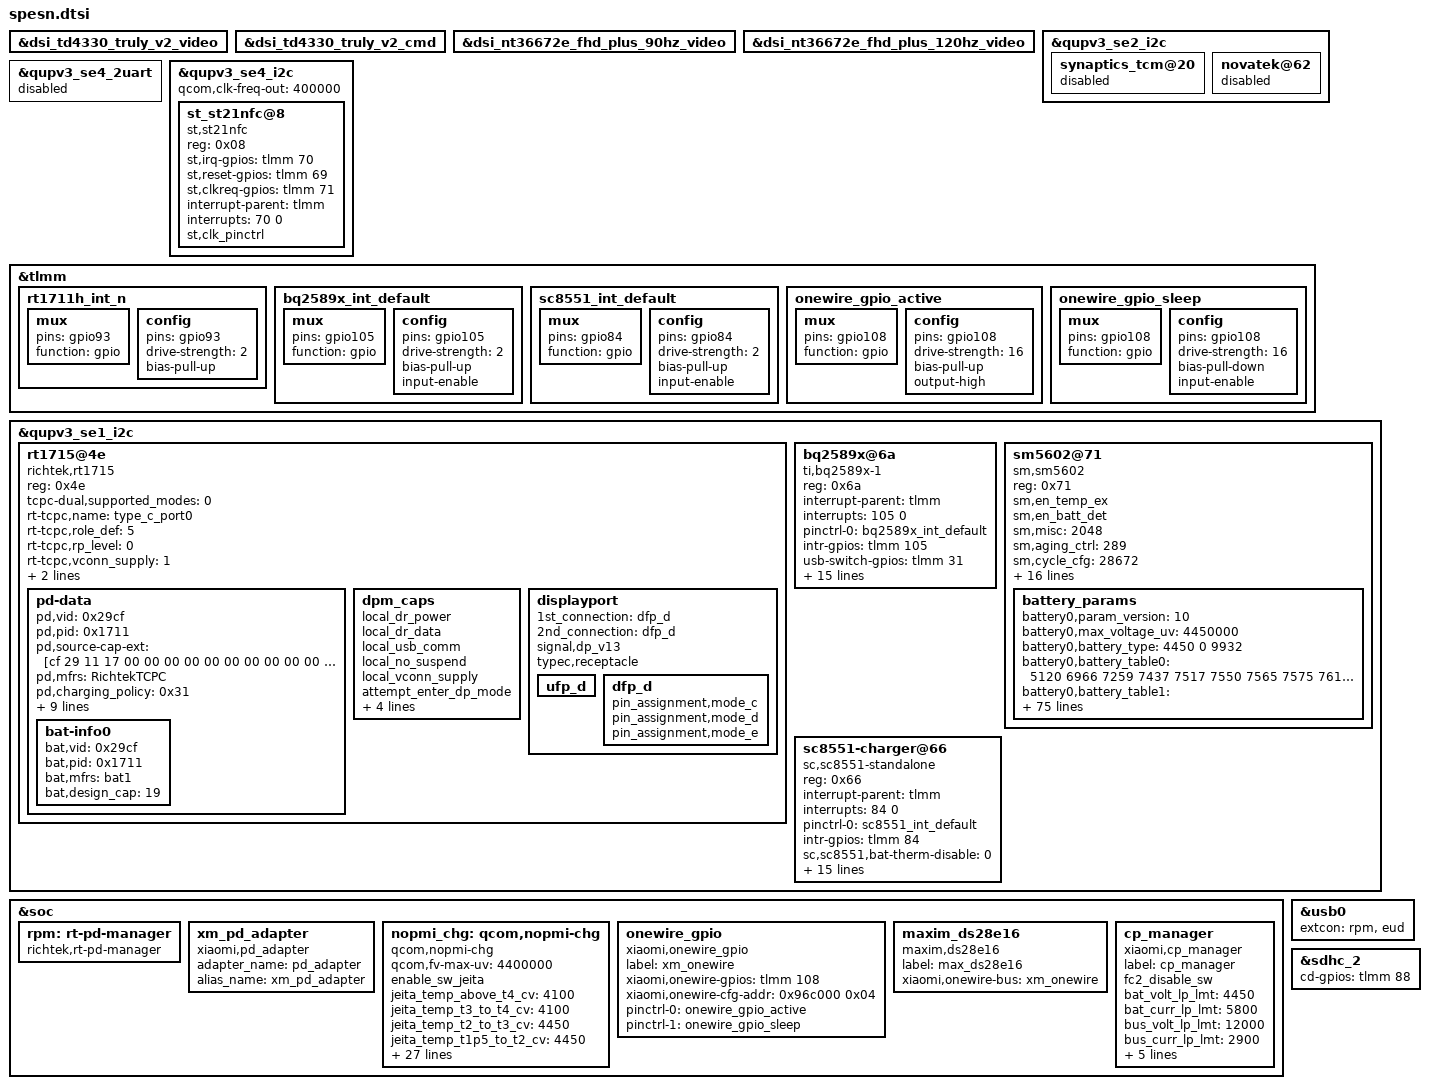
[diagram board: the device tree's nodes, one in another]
#include "khaje-idp.dtsi"

&dsi_td4330_truly_v2_video {
	/delete-property/ qcom,esd-check-enabled;
};

&dsi_td4330_truly_v2_cmd {
	/delete-property/ qcom,esd-check-enabled;
};

&dsi_nt36672e_fhd_plus_90hz_video {
	/delete-property/ qcom,esd-check-enabled;
};

&dsi_nt36672e_fhd_plus_120hz_video {
	/delete-property/ qcom,esd-check-enabled;
};

&qupv3_se2_i2c {
	synaptics_tcm@20 {
		status = "disabled";
	};

	novatek@62 {
		status = "disabled";
	};
};

&qupv3_se4_2uart {
	status = "disabled";
};

/* Spes NFC */
&qupv3_se4_i2c {
	status = "ok";
	qcom,clk-freq-out = <400000>;
	#address-cells = <1>;
	#size-cells = <0>;

	st_st21nfc@8 {
		compatible = "st,st21nfc";
		reg = <0x08>;
		st,irq-gpios = <&tlmm 70 0>;
		st,reset-gpios = <&tlmm 69 0>;
		st,clkreq-gpios = <&tlmm 71 0>;
		interrupt-parent = <&tlmm>;
		interrupts = <70 0>;
		interrupt-names = "nfc_irq";
		clock-names = "nfc_ref_clk";
		st,clk_pinctrl;
	};
};

&tlmm {
	/* RT1711H - TCPC */
	rt1711h_int_n: rt1711h_int_n {
		mux {
			pins = "gpio93";
			function = "gpio";
		};

		config {
			pins = "gpio93";
			drive-strength = <2>;
			bias-pull-up;
		};
	};

	/* BQ-CHARGER */
	bq2589x_int_default: bq2589x_int_default {
		mux {
			pins = "gpio105";
			function = "gpio";
		};

		config {
			pins = "gpio105";
			drive-strength = <2>;
			bias-pull-up;
			input-enable;
		};
	};

	/* sc8551-charger */
	sc8551_int_default: sc8551_int_default {
		mux {
			pins = "gpio84";
			function = "gpio";
		};

		config {
			pins = "gpio84";
			drive-strength = <2>;
			bias-pull-up;
			input-enable;
		};
	};

	/* Onewire */
	onewire_gpio_active: onewire_gpio_active {
		mux {
			pins = "gpio108";
			function = "gpio";
		};

		config {
			pins = "gpio108";
			drive-strength = <16>;
			bias-pull-up;
			output-high;
		};
	};

	onewire_gpio_sleep: onewire_gpio_sleep {
		mux {
			pins = "gpio108";
			function = "gpio";
		};

		config {
			pins = "gpio108";
			drive-strength = <16>;
			bias-pull-down;
			input-enable;
		};
	};
};

&qupv3_se1_i2c {
	status = "ok";
	#address-cells = <1>;
	#size-cells = <0>;

	/* TCPC: Richtek RT1715 Type-C PD Controller */
	rt1715@4e {
		compatible = "richtek,rt1715";
		reg = <0x4e>;
		status = "okay";
		tcpc-dual,supported_modes = <0>;
		rt-tcpc,name = "type_c_port0";
		/* 0: Unknown, 1: SNK, 2: SRC, 3: DRP, 4: Try.SRC, 5: Try.SNK */
		rt-tcpc,role_def = <5>;
		/* 0: Default, 1: 1.5A, 2: 3.0A */
		rt-tcpc,rp_level = <0>;
		/* 0: Never, 1: Always, 2: EMarkOnly, 3: StartOnly */
		rt-tcpc,vconn_supply = <1>;
		rt1711hpd,intr-gpios = <&tlmm 93 0>;
		pinctrl-names = "default";
		pinctrl-0 = <&rt1711h_int_n>;

		pd-data {
			pd,vid = <0x29cf>;
			pd,pid = <0x1711>;
			pd,source-cap-ext = [cf 29 11 17 00 00 00 00 00 00 00 00 00 00 00 00 00 00 00 00 00 00 00 02 00];
			pd,mfrs = "RichtekTCPC";
			/*
			 * VSAFE5V = 0x00, MAX_POWER = 0x01, CUSTOM = 0x02
			 * MAX_POWER_LV = 0x21, MAX_POWER_LVIC = 0x31
			 * MAX_POWER_HV = 0x41, MAX_POWER_HVIC = 0x51
			 */
			pd,charging_policy = <0x31>;

			/*
			 * Fixed 5V, 500 mA = <0x00019032>
			 * Fixed 5V, 1A = <0x00019064>
			 * Fixed 5V, 1.5A = <0x00019096>
			 * Fixed 5V, 2A = <0x000190c8>
			 * Fixed 5V, 3A = <0x0001912c>
			 * Fixed 9V, 500 mA = <0x0002d032>
			 * Fixed 9V, 1A = <0x0002d064>
			 * Fixed 9V, 2A = <0x0002d0c8>
			 * Fixed 9V, 3A = <0x0002d12c>
			 * Variable 5-9V, 1A = <0x8642d064>
			 * Variable 5-9V, 2A = <0x8642d0c8>
			 * Variable 5-9V, 3A = <0x8642d12c>
			 * PPS 3V ~ 5.9V, 3A = <0xC0761E3C>
			 * PPS 5V ~ 11.0V, 3A = <0xC0DC323C>
			 */
			pd,source-pdo-size = <1>;
			pd,source-pdo-data = <0x00019032>;
			pd,sink-pdo-size = <1>;
			pd,sink-pdo-data = <0x000190c8>;
			pd,id-vdo-size = <6>;
			pd,id-vdo-data = <0xd14029cf 0x0 0x17110000 0x61000000 0x0 0x41000000>;
			bat,nr = <1>;
			pd,country_nr = <0>;
			bat-info0 {
				bat,vid = <0x29cf>;
				bat,pid = <0x1711>;
				bat,mfrs = "bat1";
				bat,design_cap = <19>;
			};
		};

		dpm_caps {
			local_dr_power;
			local_dr_data;
			local_usb_comm;
			local_no_suspend;
			local_vconn_supply;
			attempt_enter_dp_mode;
			attempt_discover_cable;
			attempt_discover_id;
			pr_check = <0>;
			dr_check = <0>;
		};

		displayport {
			1st_connection = "dfp_d";
			2nd_connection = "dfp_d";
			signal,dp_v13;
			typec,receptacle;

			ufp_d {};

			dfp_d {
				pin_assignment,mode_c;
				pin_assignment,mode_d;
				pin_assignment,mode_e;
			};
		};
	};

	/* BQ charger */
	bq2589x@6a {
		compatible = "ti,bq2589x-1";
		reg = <0x6a>;
		interrupt-parent = <&tlmm>;
		interrupts = <105 0>;
		pinctrl-names = "default";
		pinctrl-0 = <&bq2589x_int_default>;
		intr-gpios = <&tlmm 105 0>;
		usb-switch-gpios = <&tlmm 31 0>;
		ti,bq2589x,vbus-volt-high-level = <8700>;
		ti,bq2589x,vbus-volt-low-level = <4400>;
		ti,bq2589x,vbat-min-volt-to-tuneup = <3000>;
		ti,bq2589x,charge-voltage = <4450>;
		ti,bq2589x,charge-current = <2000>;
		ti,bq2589x,charge-current-1500 = <1500>;
		ti,bq2589x,charge-current-1000 = <1000>;
		ti,bq2589x,charge-current-500 = <500>;
		ti,bq2589x,charge-current-3500 = <3500>;
		ti,bq2589x,input-current-2000 = <2000>;
		ti,bq2589x,term-current = <256>;
		ti,bq2589x,enable-auto-dpdm;
		ti,bq2589x,enable-termination;
		ti,bq2589x,enable-ico;
		ti,bq2589x,use-absolute-vindpm;
	};

	/* Fuel gauge */
	sm5602@71 {
		compatible = "sm,sm5602";
		reg = <0x71>;
		sm,en_temp_ex;
		sm,en_batt_det;
		sm,misc = <2048>;
		sm,aging_ctrl = <289>;
		sm,cycle_cfg = <28672>;
		sm,rsns = <0>;
		sm,fg_irq_set = <2047>;
		sm,low_soc1 = <1>;
		sm,low_soc2 = <15>;
		sm,v_l_alarm = <3400>;
		sm,v_h_alarm = <4450>;
		sm,battery_table_num = <0>;
		sm,param_version = <5>;
		sm,t_l_alarm_in = <54>;
		sm,t_h_alarm_in = <1>;
		sm,t_l_alarm_ex = <54834>;
		sm,t_h_alarm_ex = <38239>;
		sm,shutdown-delay-enable;
		sm,rtrace = <7300>;
		sm,soc_decimal_rate = <0 38 10 35 20 33 30 33 40 33 50 33 60 33 70 30 80 25 90 20 95 10>;

		battery_params {
			/* battery 0 */
			battery0,param_version = <10>;
			battery0,max_voltage_uv = <4450000>;
			battery0,battery_type = <4450 0 9932>;
			battery0,battery_table0 = <5120 6966 7259 7437 7517 7550 7565 7575 7617 7664 7706 7754 7786 7842 7918 7991 8121 8213 8313 8424 8604 8791 9041 9420>;
			battery0,battery_table1 = <0 102 490 879 1138 1396 2044 2820 3597 4632 5927 7221 8515 10457 12398 13692 14987 16281 17575 18869 20811 22752 25600 25830>;
			battery0,battery_table2 = <5664 4371 3856 3342 3084 2827 2570 2570>;
			battery0,alpha = <204>;
			battery0,beta = <37>;
			battery0,rs = <95>;
			battery0,rs_value = <80 266 14336 72>;
			battery0,vit_period = <12890>;
			battery0,volt_cal = <32768>;
			battery0,mix_value = <3>;
			battery0,curr_offset = <0>;
			battery0,curr_slope = <32896>;
			battery0,topoff_soc = <7 300 100>;
			battery0,temp_std = <25>;
			battery0,temp_offset = <0 11 1 0 8 (-1)>;
			battery0,temp_cal = <0 6 1 11 (-1) 0 6 1 9 1>;
			battery0,ext_temp_cal = <0 2 1 2 1 1 2 7 2 9>;
			battery0,tempoff = <3400 100>;
			battery0,fcm_offset = <64>;
			battery0,thermal_table = <40261 40191 40119 40045 39971 39898 39826 39758 39692 39632 39577 39529 39487 39449 39414 39379 39344 39307 39265 39217 39162 39093 39009 38911 38803 38688 38569 38449 38331 38217 38112 38012 37913 37816 37719 37622 37527 37432 37338 37244 37150 37058 36969 36882 36796 36710 36622 36532 36439 36342 36240 36130 36010 35884 35754 35621 35487 35356 35228 35106 34992 34886 34785 34688 34594 34502 34410 34317 34223 34125 34023 33921 33824 33728 33631 33531 33425 33310 33184 33045 32890 32684 32408 32081 31720 31345 30976 30630 30327 30085 29924 29819 29730 29654 29588 29529 29473 29416 29357 29290 29213 29126 29032 28933 28830 28725 28619 28513 28409 28309 28213 28122 28033 27946 27861 27777 27693 27609 27524 27437 27349 27259 27167 27074 26980 26886 26792 26698 26605 26513 26422 26333 26246 26160 26075 25990 25905 25819 25732 25643 25551 25456 25358 25258 25156 25053 24950 24849 24748 24651 24556 24463 24371 24280 24190 24101 24013 23928 23846 23766 23689 23615 23544 23476 23409 23344 23280 23217 23153 23090 23026 22963 22902 22843 22784 22725 22665 22603 22538 22471 22399 22321 22235 22144 22048 21951 21853 21757 21663 21574 21492 21414 21336 21260 21185 21113 21043 20976 20913 20853 20798 20748 20704 20663 20625 20588 20550 20511 20469 20422 20369 20307 20233 20152 20064 19973 19881 19791 19704 19624 19553 19489 19428 19371 19315 19262 19209 19157 19105 19053 18999 18945 18892 18839 18786 18733 18680 18627 18573 18518 18462 18405 18348 18290 18232 18173 18113 18052 17989 17925 17859 17790 17716 17640 17562 17482 17403 17324 17248 17174 17104 17037 16973 16910 16848 16787 16727 16668 16609 16549 16489 16429 16368 16308 16249 16189 16130 16070 16012 15953 15895 15837 15780 15722 15665 15609 15552 15496 15440 15384 15329 15274 15219 15165 15110 15057 15003 14949 14896 14843 14790 14737 14685 14632 14580 14528 14476 14425 14374 14323 14272 14222 14171 14121 14072 14022 13973 13924 13876 13827 13779 13731 13684 13636 13589 13543 13496 13450 13404 13358 13312 13267 13221 13176 13131 13087 13042 12998 12954 12910 12866 12822 12778 12735 12691 12647 12604 12561 12518 12476 12434 12392 12351 12310 12269 12229 12188 12148 12108 12069 12029 11990 11951 11912 11873 11835 11796 11758 11720 11682 11644 11606 11568 11530 11493 11455 11417 11380 11343 11306 11270 11234 11198 11162 11127 11092 11057 11022 10987 10953 10918 10883 10849 10815 10780 10746 10713 10679 10645 10612 10579 10546 10514 10482 10450 10418 10386 10354 10323 10291 10260 10229 10197 10166 10134 10103 10072 10041 10010 9980 9950 9920 9891 9862 9833 9804 9776 9747 9719 9690 9662 9634 9605 9577 9548 9520 9492 9464 9436 9408 9381 9354 9327 9300 9273 9247 9220 9194 9168 9142 9116 9090 9065 9039 9014 8989 8964 8939 8914 8890 8865 8841 8816 8792 8768 8744 8720 8696 8672 8649 8625 8602 8578 8555 8532 8508 8485 8463 8440 8417 8395 8373 8351 8329 8307 8286 8264 8243 8221 8200 8179 8158 8137 8116 8095 8074 8053 8033 8012 7992 7971 7951 7930 7910 7889 7869 7849 7829 7809 7789 7769 7749 7730 7711 7691 7672 7653 7634 7615 7597 7578 7560 7541 7523 7505 7487 7470 7452 7434 7417 7399 7381 7364 7347 7329 7312 7295 7278 7261 7244 7227 7210 7193 7177 7160 7143 7127 7110 7094 7077 7061 7045 7029 7013 6997 6981 6965 6949 6934 6918 6903 6888 6873 6857 6843 6828 6813 6798 6783 6769 6754 6739 6725 6710 6696 6681 6667 6652 6638 6624 6610 6596 6582 6569 6555 6542 6528 6515 6501 6488 6475 6462 6449 6436 6423 6410 6398 6385 6372 6360 6347 6334 6322 6309 6297 6284 6271 6259 6247 6234 6222 6210 6198 6185 6173 6161 6149 6137 6125 6114 6102 6090 6079 6067 6056 6045 6033 6022 6011 6000 5989 5978 5967 5956 5946 5935 5924 5914 5903 5893 5882 5872 5861 5851 5840 5830 5820 5809 5799 5789 5779 5769 5759 5749 5739 5729 5720 5710 5700 5691 5681 5671 5662 5652 5643 5633 5624 5615 5605 5596 5587 5578 5569 5560 5551 5541 5533 5524 5515 5506 5497 5488 5480 5471 5462 5454 5445 5437 5428 5420 5411 5402 5394 5385 5377 5368 5360 5352 5343 5335 5327 5319 5311 5303 5295 5288 5280 5272 5264 5257 5249 5241 5234 5226 5218 5211 5203 5196 5188 5180 5173 5166 5158 5151 5143 5136 5129 5122 5114 5107 5100 5093 5086 5079 5072 5065 5058 5051 5044 5037 5030 5023 5017 5010 5003 4997 4990 4983 4977 4970 4964 4958 4951 4945 4938 4932 4926 4920 4913 4907 4901 4895 4889 4883 4877 4871 4865 4859 4854 4848 4842 4836 4830 4825 4819 4813 4807 4802 4796 4791 4785 4779 4774 4769 4763 4758 4752 4747 4742 4736 4731 4726 4720 4715 4709 4704 4698 4693 4688 4682 4677 4672 4667 4661 4656 4651 4646 4641 4636 4631 4626 4621 4616 4611 4606 4601 4596 4591 4587 4582 4577 4572 4567 4563 4558 4553 4549 4544 4539 4535 4530 4525 4521 4516 4512 4507 4503 4498 4494 4489 4485 4481 4476 4472 4468 4463 4459 4455 4450 4446 4442 4438 4434 4430 4426 4422 4418 4414 4410 4406 4402 4398 4394 4390 4386 4382 4378 4375 4371 4367 4363 4359 4355 4352 4348 4344 4341 4337 4333 4330 4326 4322 4319 4315 4311 4308 4304 4301 4297 4294 4290 4287 4283 4280 4276 4273 4270 4266 4263 4259 4256 4253 4249 4246 4242 4239 4235 4232 4229 4225 4222 4219 4215 4212 4209 4206 4203 4199 4196 4193 4190 4187 4184 4181 4178 4175 4172 4169 4166 4163 4160 4157 4154 4151 4148 4145 4142 4139 4136 4133 4130 4127 4124 4121 4119 4116 4113 4110 4108 4105 4102 4099 4096 4094 4091 4088 4085 4082 4079 4077 4074 4071 4069 4066 4063 4061 4058 4056 4053 4051 4048 4045 4043 4040 4038 4035 4033 4030 4028 4025 4023 4021 4018 4016 4014 4011 4009 4007 4005 4002 4000 3998 3996 3993 3991 3989 3987 3985 3982 3980 3978>;
			/* battery 1 */
			battery1,param_version = <10>;
			battery1,max_voltage_uv = <4450000>;
			battery1,battery_type = <4450 0 9932>;
			battery1,battery_table0 = <5120 6966 7259 7437 7517 7550 7565 7575 7617 7664 7706 7754 7786 7842 7918 7991 8121 8213 8313 8424 8604 8791 9041 9420>;
			battery1,battery_table1 = <0 102 490 879 1138 1396 2044 2820 3597 4632 5927 7221 8515 10457 12398 13692 14987 16281 17575 18869 20811 22752 25600 25830>;
			battery1,battery_table2 = <5664 4371 3856 3342 3084 2827 2570 2570>;
			battery1,alpha = <204>;
			battery1,beta = <37>;
			battery1,rs = <95>;
			battery1,rs_value = <80 266 14336 72>;
			battery1,vit_period = <12890>;
			battery1,volt_cal = <32768>;
			battery1,mix_value = <3>;
			battery1,curr_offset = <0>;
			battery1,curr_slope = <32896>;
			battery1,topoff_soc = <7 300 100>;
			battery1,temp_std = <25>;
			battery1,temp_offset = <0 11 1 0 8 (-1)>;
			battery1,temp_cal = <0 6 1 11 (-1) 0 6 1 9 1>;
			battery1,ext_temp_cal = <0 2 1 2 1 1 2 7 2 9>;
			battery1,tempoff = <3400 100>;
			battery1,fcm_offset = <64>;
			battery1,thermal_table = <40261 40191 40119 40045 39971 39898 39826 39758 39692 39632 39577 39529 39487 39449 39414 39379 39344 39307 39265 39217 39162 39093 39009 38911 38803 38688 38569 38449 38331 38217 38112 38012 37913 37816 37719 37622 37527 37432 37338 37244 37150 37058 36969 36882 36796 36710 36622 36532 36439 36342 36240 36130 36010 35884 35754 35621 35487 35356 35228 35106 34992 34886 34785 34688 34594 34502 34410 34317 34223 34125 34023 33921 33824 33728 33631 33531 33425 33310 33184 33045 32890 32684 32408 32081 31720 31345 30976 30630 30327 30085 29924 29819 29730 29654 29588 29529 29473 29416 29357 29290 29213 29126 29032 28933 28830 28725 28619 28513 28409 28309 28213 28122 28033 27946 27861 27777 27693 27609 27524 27437 27349 27259 27167 27074 26980 26886 26792 26698 26605 26513 26422 26333 26246 26160 26075 25990 25905 25819 25732 25643 25551 25456 25358 25258 25156 25053 24950 24849 24748 24651 24556 24463 24371 24280 24190 24101 24013 23928 23846 23766 23689 23615 23544 23476 23409 23344 23280 23217 23153 23090 23026 22963 22902 22843 22784 22725 22665 22603 22538 22471 22399 22321 22235 22144 22048 21951 21853 21757 21663 21574 21492 21414 21336 21260 21185 21113 21043 20976 20913 20853 20798 20748 20704 20663 20625 20588 20550 20511 20469 20422 20369 20307 20233 20152 20064 19973 19881 19791 19704 19624 19553 19489 19428 19371 19315 19262 19209 19157 19105 19053 18999 18945 18892 18839 18786 18733 18680 18627 18573 18518 18462 18405 18348 18290 18232 18173 18113 18052 17989 17925 17859 17790 17716 17640 17562 17482 17403 17324 17248 17174 17104 17037 16973 16910 16848 16787 16727 16668 16609 16549 16489 16429 16368 16308 16249 16189 16130 16070 16012 15953 15895 15837 15780 15722 15665 15609 15552 15496 15440 15384 15329 15274 15219 15165 15110 15057 15003 14949 14896 14843 14790 14737 14685 14632 14580 14528 14476 14425 14374 14323 14272 14222 14171 14121 14072 14022 13973 13924 13876 13827 13779 13731 13684 13636 13589 13543 13496 13450 13404 13358 13312 13267 13221 13176 13131 13087 13042 12998 12954 12910 12866 12822 12778 12735 12691 12647 12604 12561 12518 12476 12434 12392 12351 12310 12269 12229 12188 12148 12108 12069 12029 11990 11951 11912 11873 11835 11796 11758 11720 11682 11644 11606 11568 11530 11493 11455 11417 11380 11343 11306 11270 11234 11198 11162 11127 11092 11057 11022 10987 10953 10918 10883 10849 10815 10780 10746 10713 10679 10645 10612 10579 10546 10514 10482 10450 10418 10386 10354 10323 10291 10260 10229 10197 10166 10134 10103 10072 10041 10010 9980 9950 9920 9891 9862 9833 9804 9776 9747 9719 9690 9662 9634 9605 9577 9548 9520 9492 9464 9436 9408 9381 9354 9327 9300 9273 9247 9220 9194 9168 9142 9116 9090 9065 9039 9014 8989 8964 8939 8914 8890 8865 8841 8816 8792 8768 8744 8720 8696 8672 8649 8625 8602 8578 8555 8532 8508 8485 8463 8440 8417 8395 8373 8351 8329 8307 8286 8264 8243 8221 8200 8179 8158 8137 8116 8095 8074 8053 8033 8012 7992 7971 7951 7930 7910 7889 7869 7849 7829 7809 7789 7769 7749 7730 7711 7691 7672 7653 7634 7615 7597 7578 7560 7541 7523 7505 7487 7470 7452 7434 7417 7399 7381 7364 7347 7329 7312 7295 7278 7261 7244 7227 7210 7193 7177 7160 7143 7127 7110 7094 7077 7061 7045 7029 7013 6997 6981 6965 6949 6934 6918 6903 6888 6873 6857 6843 6828 6813 6798 6783 6769 6754 6739 6725 6710 6696 6681 6667 6652 6638 6624 6610 6596 6582 6569 6555 6542 6528 6515 6501 6488 6475 6462 6449 6436 6423 6410 6398 6385 6372 6360 6347 6334 6322 6309 6297 6284 6271 6259 6247 6234 6222 6210 6198 6185 6173 6161 6149 6137 6125 6114 6102 6090 6079 6067 6056 6045 6033 6022 6011 6000 5989 5978 5967 5956 5946 5935 5924 5914 5903 5893 5882 5872 5861 5851 5840 5830 5820 5809 5799 5789 5779 5769 5759 5749 5739 5729 5720 5710 5700 5691 5681 5671 5662 5652 5643 5633 5624 5615 5605 5596 5587 5578 5569 5560 5551 5541 5533 5524 5515 5506 5497 5488 5480 5471 5462 5454 5445 5437 5428 5420 5411 5402 5394 5385 5377 5368 5360 5352 5343 5335 5327 5319 5311 5303 5295 5288 5280 5272 5264 5257 5249 5241 5234 5226 5218 5211 5203 5196 5188 5180 5173 5166 5158 5151 5143 5136 5129 5122 5114 5107 5100 5093 5086 5079 5072 5065 5058 5051 5044 5037 5030 5023 5017 5010 5003 4997 4990 4983 4977 4970 4964 4958 4951 4945 4938 4932 4926 4920 4913 4907 4901 4895 4889 4883 4877 4871 4865 4859 4854 4848 4842 4836 4830 4825 4819 4813 4807 4802 4796 4791 4785 4779 4774 4769 4763 4758 4752 4747 4742 4736 4731 4726 4720 4715 4709 4704 4698 4693 4688 4682 4677 4672 4667 4661 4656 4651 4646 4641 4636 4631 4626 4621 4616 4611 4606 4601 4596 4591 4587 4582 4577 4572 4567 4563 4558 4553 4549 4544 4539 4535 4530 4525 4521 4516 4512 4507 4503 4498 4494 4489 4485 4481 4476 4472 4468 4463 4459 4455 4450 4446 4442 4438 4434 4430 4426 4422 4418 4414 4410 4406 4402 4398 4394 4390 4386 4382 4378 4375 4371 4367 4363 4359 4355 4352 4348 4344 4341 4337 4333 4330 4326 4322 4319 4315 4311 4308 4304 4301 4297 4294 4290 4287 4283 4280 4276 4273 4270 4266 4263 4259 4256 4253 4249 4246 4242 4239 4235 4232 4229 4225 4222 4219 4215 4212 4209 4206 4203 4199 4196 4193 4190 4187 4184 4181 4178 4175 4172 4169 4166 4163 4160 4157 4154 4151 4148 4145 4142 4139 4136 4133 4130 4127 4124 4121 4119 4116 4113 4110 4108 4105 4102 4099 4096 4094 4091 4088 4085 4082 4079 4077 4074 4071 4069 4066 4063 4061 4058 4056 4053 4051 4048 4045 4043 4040 4038 4035 4033 4030 4028 4025 4023 4021 4018 4016 4014 4011 4009 4007 4005 4002 4000 3998 3996 3993 3991 3989 3987 3985 3982 3980 3978>;
			/* battery 2 */
			battery2,param_version = <10>;
			battery2,max_voltage_uv = <4450000>;
			battery2,battery_type = <4450 0 9881>;
			battery2,battery_table0 = <5120 6984 7279 7406 7498 7549 7565 7579 7629 7683 7726 7772 7803 7839 7913 7983 8118 8208 8307 8417 8596 8788 9041 9420>;
			battery2,battery_table1 = <0 101 493 755 1016 1278 1801 2847 3762 5070 6377 7685 8993 10300 12262 13569 14877 16185 17492 18800 20761 22723 25600 25830>;
			battery2,battery_table2 = <5664 4371 3856 3342 3084 2827 2570 2570>;
			battery2,alpha = <204>;
			battery2,beta = <37>;
			battery2,rs = <95>;
			battery2,rs_value = <80 266 14336 72>;
			battery2,vit_period = <12890>;
			battery2,volt_cal = <32768>;
			battery2,mix_value = <3>;
			battery2,curr_offset = <0>;
			battery2,curr_slope = <32896>;
			battery2,topoff_soc = <7 300 100>;
			battery2,temp_std = <25>;
			battery2,temp_offset = <0 11 1 0 8 (-1)>;
			battery2,temp_cal = <0 6 1 11 (-1) 0 6 1 9 1>;
			battery2,ext_temp_cal = <0 2 1 2 1 1 2 7 2 9>;
			battery2,tempoff = <3400 100>;
			battery2,fcm_offset = <64>;
			battery2,thermal_table = <40261 40191 40119 40045 39971 39898 39826 39758 39692 39632 39577 39529 39487 39449 39414 39379 39344 39307 39265 39217 39162 39093 39009 38911 38803 38688 38569 38449 38331 38217 38112 38012 37913 37816 37719 37622 37527 37432 37338 37244 37150 37058 36969 36882 36796 36710 36622 36532 36439 36342 36240 36130 36010 35884 35754 35621 35487 35356 35228 35106 34992 34886 34785 34688 34594 34502 34410 34317 34223 34125 34023 33921 33824 33728 33631 33531 33425 33310 33184 33045 32890 32684 32408 32081 31720 31345 30976 30630 30327 30085 29924 29819 29730 29654 29588 29529 29473 29416 29357 29290 29213 29126 29032 28933 28830 28725 28619 28513 28409 28309 28213 28122 28033 27946 27861 27777 27693 27609 27524 27437 27349 27259 27167 27074 26980 26886 26792 26698 26605 26513 26422 26333 26246 26160 26075 25990 25905 25819 25732 25643 25551 25456 25358 25258 25156 25053 24950 24849 24748 24651 24556 24463 24371 24280 24190 24101 24013 23928 23846 23766 23689 23615 23544 23476 23409 23344 23280 23217 23153 23090 23026 22963 22902 22843 22784 22725 22665 22603 22538 22471 22399 22321 22235 22144 22048 21951 21853 21757 21663 21574 21492 21414 21336 21260 21185 21113 21043 20976 20913 20853 20798 20748 20704 20663 20625 20588 20550 20511 20469 20422 20369 20307 20233 20152 20064 19973 19881 19791 19704 19624 19553 19489 19428 19371 19315 19262 19209 19157 19105 19053 18999 18945 18892 18839 18786 18733 18680 18627 18573 18518 18462 18405 18348 18290 18232 18173 18113 18052 17989 17925 17859 17790 17716 17640 17562 17482 17403 17324 17248 17174 17104 17037 16973 16910 16848 16787 16727 16668 16609 16549 16489 16429 16368 16308 16249 16189 16130 16070 16012 15953 15895 15837 15780 15722 15665 15609 15552 15496 15440 15384 15329 15274 15219 15165 15110 15057 15003 14949 14896 14843 14790 14737 14685 14632 14580 14528 14476 14425 14374 14323 14272 14222 14171 14121 14072 14022 13973 13924 13876 13827 13779 13731 13684 13636 13589 13543 13496 13450 13404 13358 13312 13267 13221 13176 13131 13087 13042 12998 12954 12910 12866 12822 12778 12735 12691 12647 12604 12561 12518 12476 12434 12392 12351 12310 12269 12229 12188 12148 12108 12069 12029 11990 11951 11912 11873 11835 11796 11758 11720 11682 11644 11606 11568 11530 11493 11455 11417 11380 11343 11306 11270 11234 11198 11162 11127 11092 11057 11022 10987 10953 10918 10883 10849 10815 10780 10746 10713 10679 10645 10612 10579 10546 10514 10482 10450 10418 10386 10354 10323 10291 10260 10229 10197 10166 10134 10103 10072 10041 10010 9980 9950 9920 9891 9862 9833 9804 9776 9747 9719 9690 9662 9634 9605 9577 9548 9520 9492 9464 9436 9408 9381 9354 9327 9300 9273 9247 9220 9194 9168 9142 9116 9090 9065 9039 9014 8989 8964 8939 8914 8890 8865 8841 8816 8792 8768 8744 8720 8696 8672 8649 8625 8602 8578 8555 8532 8508 8485 8463 8440 8417 8395 8373 8351 8329 8307 8286 8264 8243 8221 8200 8179 8158 8137 8116 8095 8074 8053 8033 8012 7992 7971 7951 7930 7910 7889 7869 7849 7829 7809 7789 7769 7749 7730 7711 7691 7672 7653 7634 7615 7597 7578 7560 7541 7523 7505 7487 7470 7452 7434 7417 7399 7381 7364 7347 7329 7312 7295 7278 7261 7244 7227 7210 7193 7177 7160 7143 7127 7110 7094 7077 7061 7045 7029 7013 6997 6981 6965 6949 6934 6918 6903 6888 6873 6857 6843 6828 6813 6798 6783 6769 6754 6739 6725 6710 6696 6681 6667 6652 6638 6624 6610 6596 6582 6569 6555 6542 6528 6515 6501 6488 6475 6462 6449 6436 6423 6410 6398 6385 6372 6360 6347 6334 6322 6309 6297 6284 6271 6259 6247 6234 6222 6210 6198 6185 6173 6161 6149 6137 6125 6114 6102 6090 6079 6067 6056 6045 6033 6022 6011 6000 5989 5978 5967 5956 5946 5935 5924 5914 5903 5893 5882 5872 5861 5851 5840 5830 5820 5809 5799 5789 5779 5769 5759 5749 5739 5729 5720 5710 5700 5691 5681 5671 5662 5652 5643 5633 5624 5615 5605 5596 5587 5578 5569 5560 5551 5541 5533 5524 5515 5506 5497 5488 5480 5471 5462 5454 5445 5437 5428 5420 5411 5402 5394 5385 5377 5368 5360 5352 5343 5335 5327 5319 5311 5303 5295 5288 5280 5272 5264 5257 5249 5241 5234 5226 5218 5211 5203 5196 5188 5180 5173 5166 5158 5151 5143 5136 5129 5122 5114 5107 5100 5093 5086 5079 5072 5065 5058 5051 5044 5037 5030 5023 5017 5010 5003 4997 4990 4983 4977 4970 4964 4958 4951 4945 4938 4932 4926 4920 4913 4907 4901 4895 4889 4883 4877 4871 4865 4859 4854 4848 4842 4836 4830 4825 4819 4813 4807 4802 4796 4791 4785 4779 4774 4769 4763 4758 4752 4747 4742 4736 4731 4726 4720 4715 4709 4704 4698 4693 4688 4682 4677 4672 4667 4661 4656 4651 4646 4641 4636 4631 4626 4621 4616 4611 4606 4601 4596 4591 4587 4582 4577 4572 4567 4563 4558 4553 4549 4544 4539 4535 4530 4525 4521 4516 4512 4507 4503 4498 4494 4489 4485 4481 4476 4472 4468 4463 4459 4455 4450 4446 4442 4438 4434 4430 4426 4422 4418 4414 4410 4406 4402 4398 4394 4390 4386 4382 4378 4375 4371 4367 4363 4359 4355 4352 4348 4344 4341 4337 4333 4330 4326 4322 4319 4315 4311 4308 4304 4301 4297 4294 4290 4287 4283 4280 4276 4273 4270 4266 4263 4259 4256 4253 4249 4246 4242 4239 4235 4232 4229 4225 4222 4219 4215 4212 4209 4206 4203 4199 4196 4193 4190 4187 4184 4181 4178 4175 4172 4169 4166 4163 4160 4157 4154 4151 4148 4145 4142 4139 4136 4133 4130 4127 4124 4121 4119 4116 4113 4110 4108 4105 4102 4099 4096 4094 4091 4088 4085 4082 4079 4077 4074 4071 4069 4066 4063 4061 4058 4056 4053 4051 4048 4045 4043 4040 4038 4035 4033 4030 4028 4025 4023 4021 4018 4016 4014 4011 4009 4007 4005 4002 4000 3998 3996 3993 3991 3989 3987 3985 3982 3980 3978>;
		};
	};

	/* CP pumper */
	sc8551-charger@66 {
		compatible = "sc,sc8551-standalone";
		reg = <0x66>;
		interrupt-parent = <&tlmm>;
		interrupts = <84 0>;
		pinctrl-names = "default";
		pinctrl-0 = <&sc8551_int_default>;
		intr-gpios = <&tlmm 84 0>;
		sc,sc8551,bat-therm-disable = <0>;
		sc,sc8551,bus-therm-disable = <0>;
		sc,sc8551,bat-ovp-threshold = <4525>;
		sc,sc8551,bat-ovp-alarm-threshold = <4400>;
		sc,sc8551,bat-ocp-threshold = <8000>;
		sc,sc8551,bat-ocp-alarm-threshold = <7500>;
		sc,sc8551,bus-ovp-threshold = <12000>;
		sc,sc8551,bus-ovp-alarm-threshold = <11000>;
		sc,sc8551,bus-ocp-threshold = <3750>;
		sc,sc8551,bus-ocp-alarm-threshold = <3500>;
		sc,sc8551,bat-ucp-alarm-threshold = <2000>;
		sc,sc8551,bat-therm-threshold = <21>;
		sc,sc8551,bus-therm-threshold = <21>;
		sc,sc8551,die-therm-threshold = <125>;
		sc,sc8551,ac-ovp-threshold = <17>;
		sc,sc8551,sense-resistor-mohm = <5>;
	};
};

&soc {
	rpm: rt-pd-manager {
		compatible = "richtek,rt-pd-manager";
	};

	xm_pd_adapter {
		compatible = "xiaomi,pd_adapter";
		adapter_name = "pd_adapter";
		alias_name = "xm_pd_adapter";
	};

	nopmi_chg: qcom,nopmi-chg {
		compatible = "qcom,nopmi-chg";
		status = "okay";
		qcom,fv-max-uv = <4400000>;
		enable_sw_jeita;
		jeita_temp_above_t4_cv = <4100>;
		jeita_temp_t3_to_t4_cv = <4100>;
		jeita_temp_t2_to_t3_cv = <4450>;
		jeita_temp_t1p5_to_t2_cv = <4450>;
		jeita_temp_t1_to_t1p5_cv = <4450>;
		jeita_temp_t0_to_t1_cv = <4450>;
		jeita_temp_tn1_to_t0_cv = <4450>;
		jeita_temp_below_t0_cv = <4450>;
		temp_t4_thres = <60>;
		temp_t4_thres_minus_x_degree = <58>;
		temp_t3_thres = <48>;
		temp_t3_thres_minus_x_degree = <46>;
		temp_t2_thres = <15>;
		temp_t2_thres_plus_x_degree = <17>;
		temp_t1p5_thres = <10>;
		temp_t1p5_thres_plus_x_degree = <11>;
		temp_t1_thres = <5>;
		temp_t1_thres_plus_x_degree = <6>;
		temp_t0_thres = <0>;
		temp_t0_thres_plus_x_degree = <1>;
		temp_tn1_thres = <0xfffffff6>;
		temp_tn1_thres_plus_x_degree = <0xfffffff7>;
		temp_neg_10_thres = <0xfffffff6>;
		temp_t3_to_t4_fcc = <2350>;
		temp_t2_to_t3_fcc = <5950>;
		temp_t1p5_to_t2_fcc = <3900>;
		temp_t1_to_t1p5_fcc = <2400>;
		temp_t0_to_t1_fcc = <950>;
		temp_tn1_to_t0_fcc = <490>;
		nopmi,thermal-mitigation = <5950000 5400000 5000000 4500000 4000000 3700000 3500000 3000000 2800000 2500000 2000000 1500000 1000000 800000 500000 300000>;
	};

	onewire_gpio: onewire_gpio {
		compatible = "xiaomi,onewire_gpio";
		label = "xm_onewire";
		xiaomi,onewire-gpios = <&tlmm 108 GPIO_ACTIVE_HIGH>;
		xiaomi,onewire-cfg-addr = <0x96c000 0x04>;
		pinctrl-names = "onewire_active", "onewire_sleep";
		pinctrl-0 = <&onewire_gpio_active>;
		pinctrl-1 = <&onewire_gpio_sleep>;
		status = "okay";
	};

	maxim_ds28e16: maxim_ds28e16 {
		compatible = "maxim,ds28e16";
		label = "max_ds28e16";
		xiaomi,onewire-bus = "xm_onewire";
		status = "okay";
	};

	cp_manager: cp_manager {
		compatible = "xiaomi,cp_manager";
		label = "cp_manager";
		fc2_disable_sw;
		bat_volt_lp_lmt = <4450>;
		bat_curr_lp_lmt = <5800>;
		bus_volt_lp_lmt = <12000>;
		bus_curr_lp_lmt = <2900>;
		fc2_taper_current = <2300>;
		fc2_steps = <1>;
		min_adapter_volt_required = <9000>;
		min_adapter_curr_required = <2000>;
		min_vbat_for_cp = <3500>;
		status = "okay";
	};
};

&usb0 {
	extcon = <&rpm &eud>;
};

&sdhc_2 {
	cd-gpios = <&tlmm 88 0>;
};
